# daric register map
Vendor: cramium
Registers are 32-bit, read-write, reset 0x0 unless marked. A register's access mark holds for its fields unless they carry their own. Offsets are from the block's base; [hi:lo] are bit positions.

## UDMA_SPIS_0
Base 0x50112000
Same registers: UDMA_SPIS_1 0x50113000
0x00 REG_RX_SADDR — See file:///F:/code/cram-soc/soc_oss/rtl/ifsub/udma_spis_reg_v0.2.sv
  [11:0] r_rx_startaddr
0x04 REG_RX_SIZE — See file:///F:/code/cram-soc/soc_oss/rtl/ifsub/udma_spis_reg_v0.2.sv
  [15:0] r_rx_size
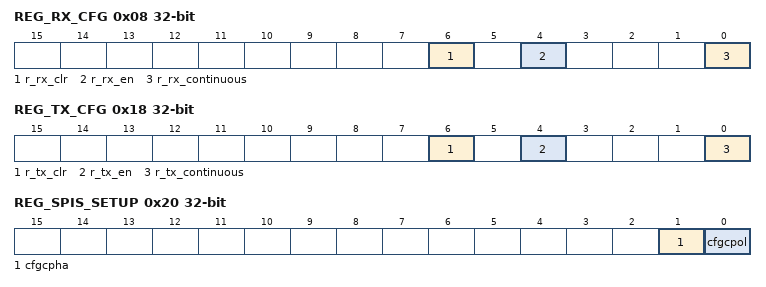
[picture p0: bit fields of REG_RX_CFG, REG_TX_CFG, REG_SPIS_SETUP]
0x08 REG_RX_CFG — See file:///F:/code/cram-soc/soc_oss/rtl/ifsub/udma_spis_reg_v0.2.sv
  [6] r_rx_clr, [4] r_rx_en, [0] r_rx_continuous
0x10 REG_TX_SADDR — See file:///F:/code/cram-soc/soc_oss/rtl/ifsub/udma_spis_reg_v0.2.sv
  [11:0] r_tx_startaddr
0x14 REG_TX_SIZE — See file:///F:/code/cram-soc/soc_oss/rtl/ifsub/udma_spis_reg_v0.2.sv
  [15:0] r_tx_size
0x18 REG_TX_CFG — See file:///F:/code/cram-soc/soc_oss/rtl/ifsub/udma_spis_reg_v0.2.sv
  [6] r_tx_clr, [4] r_tx_en, [0] r_tx_continuous
0x20 REG_SPIS_SETUP — See file:///F:/code/cram-soc/soc_oss/rtl/ifsub/udma_spis_reg_v0.2.sv
  [1] cfgcpha, [0] cfgcpol
0x24 REG_SEOT_CNT — See file:///F:/code/cram-soc/soc_oss/rtl/ifsub/udma_spis_reg_v0.2.sv
  [15:0] sr_seot_cnt
0x28 REG_SPIS_IRQ_EN — See file:///F:/code/cram-soc/soc_oss/rtl/ifsub/udma_spis_reg_v0.2.sv
  [0] seot_irq_en
0x2C REG_SPIS_RXCNT — See file:///F:/code/cram-soc/soc_oss/rtl/ifsub/udma_spis_reg_v0.2.sv
  [15:0] cfgrxcnt
0x30 REG_SPIS_TXCNT — See file:///F:/code/cram-soc/soc_oss/rtl/ifsub/udma_spis_reg_v0.2.sv
  [15:0] cfgtxcnt
0x34 REG_SPIS_DMCNT — See file:///F:/code/cram-soc/soc_oss/rtl/ifsub/udma_spis_reg_v0.2.sv
  [15:0] cfgdmcnt

## AES
Base 0x4002D000
0x00 SFR_CRFUNC — See file:///F:/code/cram-soc/soc_oss/rtl/crypto/aes_v0.4.sv
  [7:0] sfr_crfunc — sfr_crfunc read/write control register
0x04 SFR_AR — See file:///F:/code/cram-soc/soc_oss/rtl/crypto/aes_v0.4.sv
  [31:0] sfr_ar — sfr_ar performs action on write of value: 0x5a
0x08 SFR_SRMFSM — See file:///F:/code/cram-soc/soc_oss/rtl/crypto/aes_v0.4.sv
  [7:0] sfr_srmfsm — sfr_srmfsm read only status register
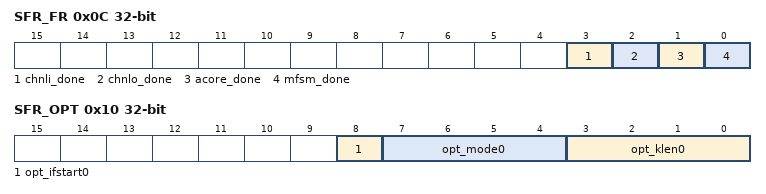
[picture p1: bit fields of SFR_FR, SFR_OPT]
0x0C SFR_FR — See file:///F:/code/cram-soc/soc_oss/rtl/crypto/aes_v0.4.sv
  [3] chnli_done — chnli_done flag register. `1` means event happened, write back `1` in respective bit position to clear the flag
  [2] chnlo_done — chnlo_done flag register. `1` means event happened, write back `1` in respective bit position to clear the flag
  [1] acore_done — acore_done flag register. `1` means event happened, write back `1` in respective bit position to clear the flag
  [0] mfsm_done — mfsm_done flag register. `1` means event happened, write back `1` in respective bit position to clear the flag
0x10 SFR_OPT — See file:///F:/code/cram-soc/soc_oss/rtl/crypto/aes_v0.4.sv
  [8] opt_ifstart0 — opt_ifstart0 read/write control register
  [7:4] opt_mode0 — opt_mode0 read/write control register
  [3:0] opt_klen0 — opt_klen0 read/write control register
0x14 SFR_OPT1 — See file:///F:/code/cram-soc/soc_oss/rtl/crypto/aes_v0.4.sv
  [15:0] sfr_opt1 — sfr_opt1 read/write control register
0x18 SFR_OPTLTX — See file:///F:/code/cram-soc/soc_oss/rtl/crypto/aes_v0.4.sv
  [5:0] sfr_optltx — sfr_optltx read/write control register
0x20 SFR_MASKSEED — See file:///F:/code/cram-soc/soc_oss/rtl/crypto/aes_v0.4.sv
  [31:0] sfr_maskseed — sfr_maskseed read/write control register
0x24 SFR_MASKSEEDAR — See file:///F:/code/cram-soc/soc_oss/rtl/crypto/aes_v0.4.sv
  [31:0] sfr_maskseedar — sfr_maskseedar performs action on write of value: 0x5a
0x30 SFR_SEGPTR_PTRID_IV — See file:///F:/code/cram-soc/soc_oss/rtl/crypto/aes_v0.4.sv
  [11:0] PTRID_IV — cr_segptrstart read/write control register
0x34 SFR_SEGPTR_PTRID_AKEY — See file:///F:/code/cram-soc/soc_oss/rtl/crypto/aes_v0.4.sv
  [11:0] PTRID_AKEY — cr_segptrstart read/write control register
0x38 SFR_SEGPTR_PTRID_AIB — See file:///F:/code/cram-soc/soc_oss/rtl/crypto/aes_v0.4.sv
  [11:0] PTRID_AIB — cr_segptrstart read/write control register
0x3C SFR_SEGPTR_PTRID_AOB — See file:///F:/code/cram-soc/soc_oss/rtl/crypto/aes_v0.4.sv
  [11:0] PTRID_AOB — cr_segptrstart read/write control register
